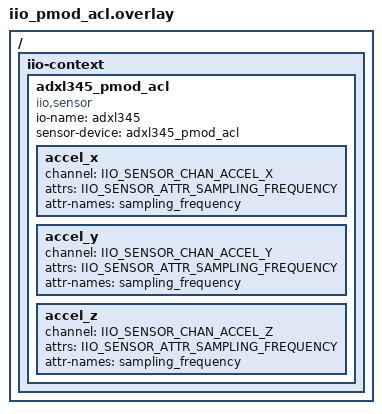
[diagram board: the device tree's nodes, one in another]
/*
 * Copyright (c) 2026 Analog Devices, Inc
 *
 * SPDX-License-Identifier: Apache-2.0
 */

#include <dt-bindings/iio/sensor-channels.h>
#include <dt-bindings/iio/sensor-attrs.h>

/ {
	iio-context {
		adxl345_pmod_acl {
			compatible = "iio,sensor";
			io-name = "adxl345";
			sensor-device = <&adxl345_pmod_acl>;

			accel_x {
				channel = <IIO_SENSOR_CHAN_ACCEL_X>;
				attrs = <IIO_SENSOR_ATTR_SAMPLING_FREQUENCY>;
				attr-names = "sampling_frequency";
			};

			accel_y {
				channel = <IIO_SENSOR_CHAN_ACCEL_Y>;
				attrs = <IIO_SENSOR_ATTR_SAMPLING_FREQUENCY>;
				attr-names = "sampling_frequency";
			};

			accel_z {
				channel = <IIO_SENSOR_CHAN_ACCEL_Z>;
				attrs = <IIO_SENSOR_ATTR_SAMPLING_FREQUENCY>;
				attr-names = "sampling_frequency";
			};
		};
	};
};
